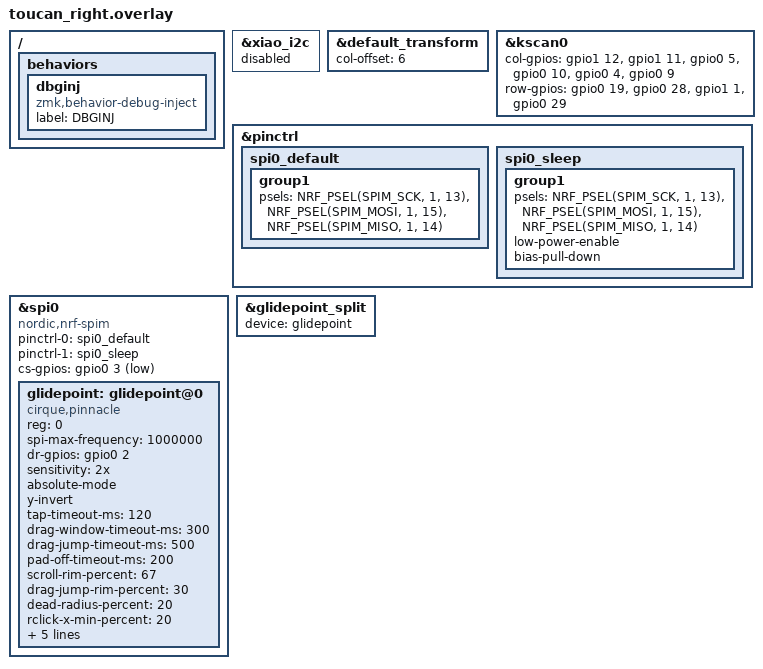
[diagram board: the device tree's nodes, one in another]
#include "toucan.dtsi"
#include <input/processors.dtsi>
#include <dt-bindings/zmk/input_transform.h>

&xiao_i2c {
    status = "disabled";
};

/ {
    behaviors {
        dbginj: dbginj {
            compatible = "zmk,behavior-debug-inject";
            #binding-cells = <2>;
            label = "DBGINJ";
        };
    };
};

&default_transform {
    col-offset = <6>;
};

&kscan0 {
    col-gpios
    = <&gpio1 12 GPIO_ACTIVE_HIGH>
    , <&gpio1 11 GPIO_ACTIVE_HIGH>
    , <&gpio0 5 GPIO_ACTIVE_HIGH>
    , <&gpio0 10 GPIO_ACTIVE_HIGH>
    , <&gpio0 4 GPIO_ACTIVE_HIGH>
    , <&gpio0 9 GPIO_ACTIVE_HIGH>
    ;

    row-gpios
    = <&gpio0 19 (GPIO_ACTIVE_HIGH | GPIO_PULL_DOWN)>
    , <&gpio0 28 (GPIO_ACTIVE_HIGH | GPIO_PULL_DOWN)>
    , <&gpio1 1 (GPIO_ACTIVE_HIGH | GPIO_PULL_DOWN)>
    , <&gpio0 29 (GPIO_ACTIVE_HIGH | GPIO_PULL_DOWN)>
    ;
};

&pinctrl {
    spi0_default: spi0_default {
        group1 {
            psels = <NRF_PSEL(SPIM_SCK, 1, 13)>,
                <NRF_PSEL(SPIM_MOSI, 1, 15)>,
                <NRF_PSEL(SPIM_MISO, 1, 14)>;
        };
    };

     spi0_sleep: spi0_sleep {
        group1 {
            psels = <NRF_PSEL(SPIM_SCK, 1, 13)>,
                    <NRF_PSEL(SPIM_MOSI, 1, 15)>,
                    <NRF_PSEL(SPIM_MISO, 1, 14)>;
            low-power-enable;
            bias-pull-down; // minimize power leakage during sleep
        };
    };

};

&spi0 {
   compatible = "nordic,nrf-spim";
   status = "okay";
   pinctrl-0 = <&spi0_default>;
   pinctrl-1 = <&spi0_sleep>;
   pinctrl-names = "default", "sleep";
   cs-gpios = <&gpio0 3 (GPIO_ACTIVE_LOW | GPIO_PULL_UP)>;  // pull-up to ensure CS is !asserted when asleep
   glidepoint:  glidepoint@0 {
        compatible = "cirque,pinnacle";
        reg = <0>;
        spi-max-frequency = <1000000>;
        status = "okay";
        dr-gpios = <&gpio0 2 (GPIO_ACTIVE_HIGH)>;
        sensitivity = "2x";
        absolute-mode;
        y-invert;

        // Optional: aggressive power saving (5s sleep, ~300ms wake latency)
        //sleep;

        // ── Gesture timing ───────────────────────────────────────────────────
        tap-timeout-ms = <120>;           // finger-down before TAP_PENDING → MOVING
        drag-window-timeout-ms = <300>;   // window for re-touch after tap to start drag
        drag-jump-timeout-ms = <500>;     // window to reposition finger across pad during drag
        pad-off-timeout-ms = <200>;       // delay before PAD layer turns off after lift

        // ── Gesture zones ────────────────────────────────────────────────────
        scroll-rim-percent = <67>;              // outer scroll ring, % of half-pad-width
        drag-jump-rim-percent = <30>;           // rim edge for drag-jump detection, % of half-pad-width
        dead-radius-percent = <20>;             // inner dead-zone, % of half-pad-width
        rclick-x-min-percent = <20>;            // right-click zone: x ≤ this % of pad width
        scroll-exclusion-zone-percent = <20>;   // centred y-band that blocks scroll initiation

        // ── Force / sensitivity ──────────────────────────────────────────────
        force-drag-z-threshold = <50>;          // min z for force-drag: TAP_PENDING/MOVING→DRAGGING
        double-click-drag-z-threshold = <20>;   // min z for tap-then-retouch: DRAG_WINDOW→DRAGGING

        // ── Scroll ───────────────────────────────────────────────────────────
        wheel-clicks = <18>;   // scroll clicks per full finger revolution

        // ── Tap behaviour ────────────────────────────────────────────────────
        tap-snap;   // uncomment to discard cursor delta accumulated during TAP_PENDING
    };
};

&glidepoint_split {
    device = <&glidepoint>;
};

